# STM32H7S register map
File version: 1.3
CPU: CM7 r0p1, little endian, MPU, FPU, 4 interrupt priority bits
Registers are 32-bit, read-write, reset 0x0 unless marked. A register's access mark holds for its fields unless they carry their own. Offsets are from the block's base; [hi:lo] are bit positions; {n}, {i} and the like mark numbered series; 'fields as' and 'values as' point back to an identical list; <NAME> marks a mode.

## RCC — RCC register block
Base 0x58024400
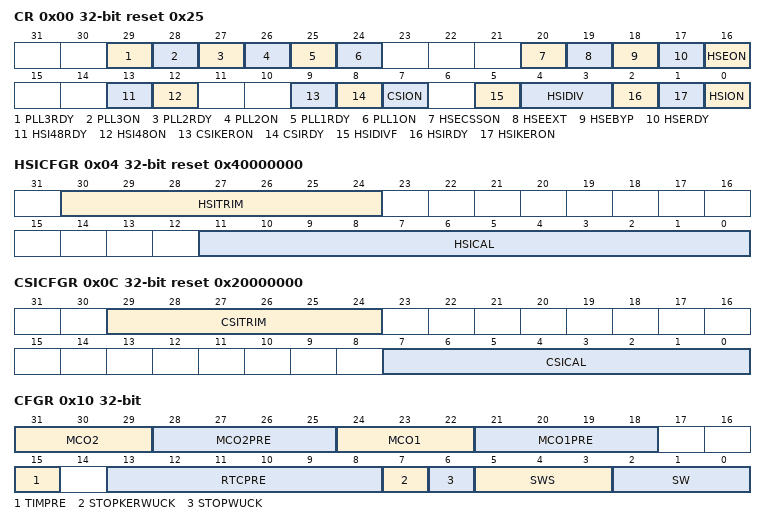
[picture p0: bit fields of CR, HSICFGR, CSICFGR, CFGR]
0x00 CR reset 0x25 — RCC source control register
  [29] PLL3RDY ro — PLL3 clock ready flag
    0=NotReady (Clock not ready); 1=Ready (Clock ready)
  [28] PLL3ON — PLL3 enable
    0=Off (Clock Off); 1=On (Clock On)
  [27] PLL2RDY ro — PLL2 clock ready flag
    0=NotReady (Clock not ready); 1=Ready (Clock ready)
  [26] PLL2ON — PLL2 enable
    0=Off (Clock Off); 1=On (Clock On)
  [25] PLL1RDY ro — PLL1 clock ready flag
    0=NotReady (Clock not ready); 1=Ready (Clock ready)
  [24] PLL1ON — PLL1 enable
    0=Off (Clock Off); 1=On (Clock On)
  [20] HSECSSON — HSE clock security system enable
    0=Off (Clock Off); 1=On (Clock On)
  [19] HSEEXT — external high speed clock type in Bypass mode
  [18] HSEBYP — HSE clock bypass
    0=NotBypassed (HSE crystal oscillator not bypassed); 1=Bypassed (HSE crystal oscillator bypassed with external clock)
  [17] HSERDY ro — HSE clock ready flag
    0=NotReady (Clock not ready); 1=Ready (Clock ready)
  [16] HSEON — HSE clock enable
    0=Off (Clock Off); 1=On (Clock On)
  [13] HSI48RDY ro — HSI48 clock ready flag
    0=NotReady (Clock not ready); 1=Ready (Clock ready)
  [12] HSI48ON — HSI48 clock enable
    0=Off (Clock Off); 1=On (Clock On)
  [9] CSIKERON — CSI clock enable in Stop mode
    0=Off (Clock Off); 1=On (Clock On)
  [8] CSIRDY ro — CSI clock ready flag
    0=NotReady (Clock not ready); 1=Ready (Clock ready)
  [7] CSION — CSI clock enable
    0=Off (Clock Off); 1=On (Clock On)
  [5] HSIDIVF ro — HSI divider flag
    0=NotPropagated (New HSIDIV ratio has not yet propagated to hsi_ck); 1=Propagated (HSIDIV ratio has propagated to hsi_ck)
  [4:3] HSIDIV — HSI clock divider
    0=Div1 (No division); 1=Div2 (Division by 2); 2=Div4 (Division by 4); 3=Div8 (Division by 8)
  [2] HSIRDY ro — HSI clock ready flag
    0=NotReady (Clock not ready); 1=Ready (Clock ready)
  [1] HSIKERON — HSI clock enable in Stop mode
    0=Off (Clock Off); 1=On (Clock On)
  [0] HSION — HSI clock enable
    0=Off (Clock Off); 1=On (Clock On)
0x04 HSICFGR reset 0x40000000 (reset mask 0xFFFFF000) — RCC HSI calibration register
  [30:24] HSITRIM — HSI clock trimming
  [11:0] HSICAL ro — HSI clock calibration
0x08 CRRCR ro (reset mask 0xFFFFF000) — RCC clock recovery RC register
  [9:0] HSI48CAL — Internal RC 48 MHz clock calibration
0x0C CSICFGR reset 0x20000000 (reset mask 0xFFFFF000) — RCC CSI calibration register
  [29:24] CSITRIM — CSI clock trimming
  [7:0] CSICAL ro — CSI clock calibration
0x10 CFGR — RCC clock configuration register
  [31:29] MCO2 — microcontroller clock output 2
    0=SYSCLK (System clock selected for micro-controller clock output); 1=PLL2_P (pll2_p selected for micro-controller clock output); 2=HSE (HSE selected for micro-controller clock output); 3=PLL1_P (pll1_p selected for micro-controller clock output); 4=CSI (CSI selected for micro-controller clock output); 5=LSI (LSI selected for micro-controller clock output)
  [28:25] MCO2PRE — MCO2 prescaler
  [24:22] MCO1 — Microcontroller clock output 1
    0=HSI (HSI selected for micro-controller clock output); 1=LSE (LSE selected for micro-controller clock output); 2=HSE (HSE selected for micro-controller clock output); 3=PLL1_Q (pll1_q selected for micro-controller clock output); 4=HSI48 (HSI48 selected for micro-controller clock output)
  [21:18] MCO1PRE — MCO1 prescaler
  [15] TIMPRE — timers clocks prescaler selection
    0=DefaultX2 (Timer kernel clock equal to 2x pclk by default); 1=DefaultX4 (Timer kernel clock equal to 4x pclk by default)
  [13:8] RTCPRE — HSE division factor for RTC clock
  [7] STOPKERWUCK — kernel clock selection after a wake up from system Stop
    0=HSI (HSI selected as wake up clock from system Stop); 1=CSI (CSI selected as wake up clock from system Stop)
  [6] STOPWUCK — system clock selection after a wake up from system Stop
    values as STOPKERWUCK
  [5:3] SWS ro — system clock switch status
    0=HSI (HSI oscillator used as system clock); 1=CSI (CSI oscillator used as system clock); 2=HSE (HSE oscillator used as system clock); 3=PLL1 (PLL1 used as system clock)
  [2:0] SW — system clock switch
    0=HSI (HSI selected as system clock); 1=CSI (CSI selected as system clock); 2=HSE (HSE selected as system clock); 3=PLL1 (PLL1 selected as system clock)
0x18 CDCFGR — RCC CPU domain clock configuration register
  [3:0] CPRE — CPU domain core prescaler
0x1C BMCFGR — RCC AHB clock configuration register
  [3:0] HPRE — Bus matrix clock prescaler
    8=Div2 (sys_ck divided by 2); 9=Div4 (sys_ck divided by 4); 10=Div8 (sys_ck divided by 8); 11=Div16 (sys_ck divided by 16); 12=Div64 (sys_ck divided by 64); 13=Div128 (sys_ck divided by 128); 14=Div256 (sys_ck divided by 256); 15=Div512 (sys_ck divided by 512); other=Div1 (sys_ck not divided)
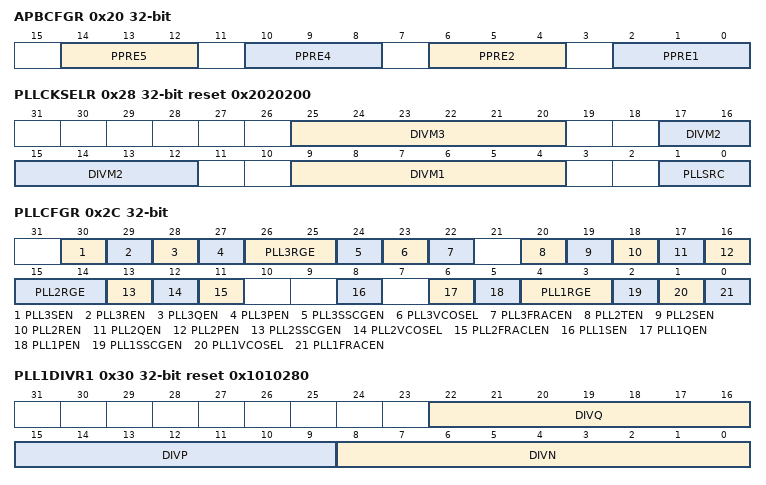
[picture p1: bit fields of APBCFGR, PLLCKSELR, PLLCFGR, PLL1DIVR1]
0x20 APBCFGR — RCC APB clocks configuration register
  [14:12] PPRE5 — CPU domain APB5 prescaler
  [10:8] PPRE4 — CPU domain APB4 prescaler
  [6:4] PPRE2 — CPU domain APB2 prescaler
  [2:0] PPRE1 — CPU domain APB1 prescaler
0x28 PLLCKSELR reset 0x2020200 — RCC PLLs clock source selection register
  [25:20] DIVM3 — prescaler for PLL3
  [17:12] DIVM2 — prescaler for PLL2
  [9:4] DIVM1 — prescaler for PLL1
  [1:0] PLLSRC — DIVMx and PLLs clock source selection
    0=HSI (HSI selected as PLL clock); 1=CSI (CSI selected as PLL clock); 2=HSE (HSE selected as PLL clock); 3=None (No clock sent to DIVMx dividers and PLLs)
0x2C PLLCFGR — RCC PLLs configuration register
  [30] PLL3SEN — PLL3 DIVS divider output enable
    0=Disabled (Clock ouput is disabled); 1=Enabled (Clock output is enabled)
  [29] PLL3REN — PLL3 DIVR divider output enable
    values as PLL3SEN
  [28] PLL3QEN — PLL3 DIVQ divider output enable
    values as PLL3SEN
  [27] PLL3PEN — PLL3 DIVP divider output enable
    values as PLL3SEN
  [26:25] PLL3RGE — PLL3 input frequency range
    0=Range1 (Frequency is between 1 and 2 MHz); 1=Range2 (Frequency is between 2 and 4 MHz); 2=Range4 (Frequency is between 4 and 8 MHz); 3=Range8 (Frequency is between 8 and 16 MHz)
  [24] PLL3SSCGEN — PLL3 SSCG enable
  [23] PLL3VCOSEL — PLL3 VCO selection
    0=WideVCO (VCO frequency range 192 to 836 MHz); 1=MediumVCO (VCO frequency range 150 to 420 MHz)
  [22] PLL3FRACEN — PLL3 fractional latch enable
    0=Reset latch to tranfer FRACN to the Sigma-Delta modulator; 1=Set (Set latch to tranfer FRACN to the Sigma-Delta modulator)
  [20] PLL2TEN — PLL2 DIVT divider output enable
    values as PLL3SEN
  [19] PLL2SEN — PLL2 DIVS divider output enable
    values as PLL3SEN
  [18] PLL2REN — PLL2 DIVR divider output enable
    values as PLL3SEN
  [17] PLL2QEN — PLL2 DIVQ divider output enable
    values as PLL3SEN
  [16] PLL2PEN — PLL2 DIVP divider output enable
    values as PLL3SEN
  [15:14] PLL2RGE — PLL2 input frequency range
    values as PLL3RGE
  [13] PLL2SSCGEN — PLL2 SSCG enable
  [12] PLL2VCOSEL — PLL2 VCO selection
    values as PLL3VCOSEL
  [11] PLL2FRACLEN — PLL2 fractional latch enable
  [8] PLL1SEN — PLL1 DIVS divider output enable
    values as PLL3SEN
  [6] PLL1QEN — PLL1 DIVQ divider output enable
    values as PLL3SEN
  [5] PLL1PEN — PLL1 DIVP divider output enable
    values as PLL3SEN
  [4:3] PLL1RGE — PLL1 input frequency range
    values as PLL3RGE
  [2] PLL1SSCGEN — PLL1 SSCG enable
  [1] PLL1VCOSEL — PLL1 VCO selection
    values as PLL3VCOSEL
  [0] PLL1FRACEN — PLL1 fractional latch enable
    values as PLL3FRACEN
0x30 PLL1DIVR1 reset 0x1010280 — RCC PLL1 dividers configuration register 1
  [22:16] DIVQ — PLL1 DIVQ division factor
  [15:9] DIVP — PLL1 DIVP division factor
  [8:0] DIVN — multiplication factor for PLL1 VCO
{0x2C+8i} PLL{i}FRACR (i=1..3) — RCC PLL{i} fractional divider register
  [15:3] FRACN — fractional part of the multiplication factor for PLL{i} VCO
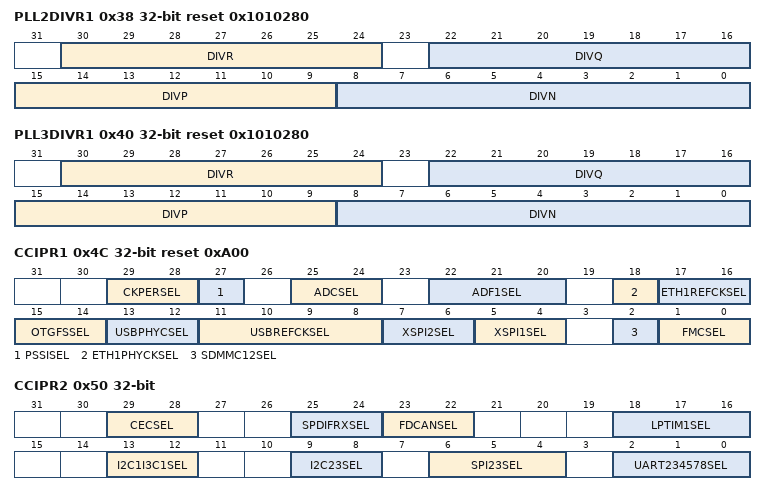
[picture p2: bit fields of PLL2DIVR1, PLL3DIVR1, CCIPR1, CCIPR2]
0x38 PLL2DIVR1 reset 0x1010280 — RCC PLL2 dividers configuration register 1
  [30:24] DIVR — PLL2 DIVR division factor
  [22:16] DIVQ — PLL2 DIVQ division factor
  [15:9] DIVP — PLL2 DIVP division factor
  [8:0] DIVN — multiplication factor for PLL2 VCO
0x40 PLL3DIVR1 reset 0x1010280 — RCC PLL3 dividers configuration register 1
  [30:24] DIVR — PLL3 DIVR division factor
  [22:16] DIVQ — PLL3 DIVQ division factor
  [15:9] DIVP — PLL3 DIVP division factor
  [8:0] DIVN — Multiplication factor for PLL3 VCO
0x4C CCIPR1 reset 0xA00 — RCC AHB peripheral kernel clock selection register
  [29:28] CKPERSEL — per_ck clock source selection
    0=HSI (HSI selected as peripheral clock); 1=CSI (CSI selected as peripheral clock); 2=HSE (HSE selected as peripheral clock)
  [27] PSSISEL — PSSI kernel clock source selection
    0=PLL3_R (pll3_r selected as peripheral clock); 1=PER (per selected as kernel peripheral clock)
  [25:24] ADCSEL — SAR ADC kernel clock source selection
    0=PLL2_P (pll2_p selected as peripheral clock); 1=PLL3_R (pll3_r selected as peripheral clock); 2=PER (per selected as peripheral clock)
  [22:20] ADF1SEL — ADF kernel clock source selection
    0=HCLK1 (hclk1 selected as ADF clock); 1=pll2_p_ck selected as ADF clock; 2=PLL3_P (pll3_p_ck selected as ADF clock); 3=I2S_CLKIN (I2S_CKIN selected as ADF clock); 4=CSI_KER (csi_ker_ck selected as ADF clock); 5=HSI_KER (hsi_ker_ck selected as ADF clock)
  [18] ETH1PHYCKSEL — Clock source selection for external Ethernet PHY
    0=HSE_KER (hse_ker selected as clock source); 1=PLL3_S (pll3_s selected clock source)
  [17:16] ETH1REFCKSEL — Ethernet reference clock source selection
    0=ETH_RMII_REF (ETH_RMII_REF selected as peripheral clock); 1=HSE_KER (hse_ker selected as peripheral clock); 2=ETH_CLK_FB (eth_clk_fb selected as peripheral clock)
  [15:14] OTGFSSEL — OTGFS kernel clock source selection
    0=HSI48_KER (hsi48_ker_ck); 1=PLL3_Q (pll3_q_ck); 2=HSE_KER (hse_ker_ck); 3=CLK48 (clk48mohci)
  [13:12] USBPHYCSEL — USBPHYC kernel clock source selection
    0=HSE_KER (hse_ker_ck); 1=HSE_KER_DIV2 (hse_ker_ck / 2); 2=PLL3_Q (pll3_q_ck)
  [11:8] USBREFCKSEL — USBPHYC kernel clock frequency selection
    3=MHz16 (The clock frequency provided to the USBPHYC is 16 MHz); 8=MHz19 (The clock frequency provided to the USBPHYC is 19.2 MHz); 9=MHz20 (The clock frequency provided to the USBPHYC is 20MHz); 10=MHz24 (The clock frequency provided to the USBPHYC is 24 MHz); 11=MHz32 (The clock frequency provided to the USBPHYC is 32 MHz); 14=MHz26 (The clock frequency provided to the USBPHYC is 26 MHz)
  [7:6] XSPI2SEL — XSPI2 kernel clock source selection
    0=RCC_HCLK5 (hclk5 selected as peripheral clock); 1=PLL2_S (pll2_s_ck selected as peripheral clock); 2=PLL2_T (pll2_t_ck selected as peripheral clock)
  [5:4] XSPI1SEL — XSPI1 kernel clock source selection
    values as XSPI2SEL
  [2] SDMMC12SEL — SDMMC1 and SDMMC2 kernel clock source selection
    0=PLL2_S (pll1_s selected as peripheral clock); 1=PLL2_T (pll2_t selected as peripheral clock)
  [1:0] FMCSEL — FMC kernel clock source selection
    0=RCC_HCLK5 (hclk5 selected as peripheral clock); 1=PLL1_Q (pll1_q selected as peripheral clock); 2=PLL2_R (pll2_r selected as peripheral clock); 3=HSI_KER (hsi_ker selected as peripheral clock)
0x50 CCIPR2 — RCC APB1 peripherals kernel clock selection register
  [29:28] CECSEL — HDMI-CEC kernel clock source selection
    0=LSE (lse selected as clock); 1=LSI (lsi selected as clock); 2=CSI_KER (csi_ker divided by 122 selected as clock)
  [25:24] SPDIFRXSEL — SPDIFRX kernel clock source selection
    0=PLL1_Q (pll1_q selected as clock); 1=PLL2_R (pll2_r selected as clock); 2=PLL3_R (pll3_r selected as clock); 3=HSI_KER (hsi_ker selected as clock)
  [23:22] FDCANSEL — FDCAN kernel clock source selection
    0=HSE_KER (hse_ker selected as clock); 1=PLL1_Q (pll1_q selected as clock); 2=PLL2_P (pll2_p selected as clock)
  [18:16] LPTIM1SEL — LPTIM1 kernel clock source selection
    0=PCLK1 (pclk1 selected as peripheral clock); 1=PLL2_P (pll2_p selected as peripheral clock); 2=PLL3_R (pll3_r selected as peripheral clock); 3=LSE (lse selected as peripheral clock); 4=LSI (lsi selected as peripheral clock); 5=PER (per selected as peripheral clock)
  [13:12] I2C1I3C1SEL — I2C1 or I3C1 kernel clock source selection
    0=PCLK1 (pclk1 selected as peripheral clock); 1=PLL3_R (pll3_r selected as peripheral clock); 2=HSI_KER (hsi_ker selected as peripheral clock); 3=CSI_KER (csi_ker selected as peripheral clock)
  [9:8] I2C23SEL — I2C2, I2C3 kernel clock source selection
    0=PCLK1 (pclk1 selected as clock); 1=PLL3_R (pll3_r selected as clock); 2=HSI_KER (hsi_ker selected as clock); 3=CSI_KER (csi_ker selected as clock)
  [6:4] SPI23SEL — SPI/I2S2 and SPI/I2S3 kernel clock source selection
    0=PLL1_Q (pll1_q selected as clock); 1=PLL2_P (pll2_p selected as clock); 2=PLL3_P (pll3_p selected as clock); 3=I2S_CKIN (I2S_CKIN selected as clock); 4=PER (per selected as clock)
  [2:0] UART234578SEL — USART2,3, UART4,5,7,8 (APB1) kernel clock source selection
    0=PCLK1 (pclk1 selected as clock); 1=PLL2_Q (pll2_q selected as clock); 2=PLL3_Q (pll3_q selected as clock); 3=HSI_KER (hsi_ker selected as clock); 4=CSI_KER (csi_ker selected as clock); 5=LSE (lse selected as clock)
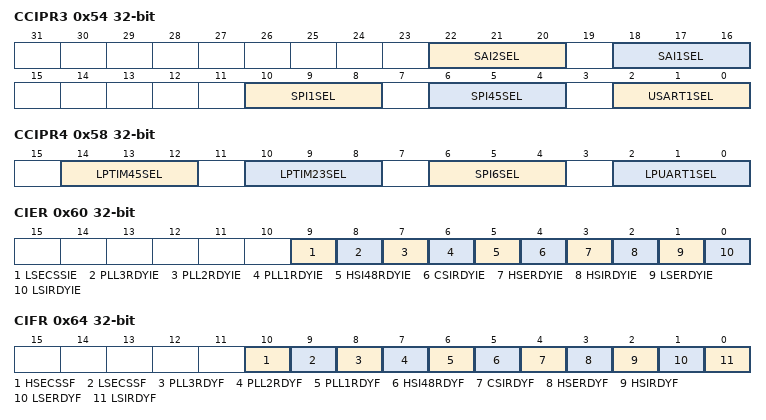
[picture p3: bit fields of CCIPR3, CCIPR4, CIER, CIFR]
0x54 CCIPR3 — RCC APB2 peripherals kernel clock selection register
  [22:20] SAI2SEL — SAI2 kernel clock source selection
    0=PLL1_Q (pll1_q selected as clock); 1=PLL2_P (pll2_p selected as clock); 2=PLL3_P (pll3_p selected as clock); 3=I2S_CKIN (I2S_CKIN selected as clock); 4=PER (per selected as clock); 5=SPDIFRX_SYMB (spdifrx_symb selected as clock)
  [18:16] SAI1SEL — SAI1 kernel clock source selection
    values as CCIPR2.SPI23SEL
  [10:8] SPI1SEL — SPI/I2S1 kernel clock source selection
    0=PLL1_Q (pll1_q selected as SPI/I2S1 and 7 clock); 1=PLL2_P (pll2_p selected as SPI/I2S1 and 7 clock); 2=PLL3_P (pll3_p selected as SPI/I2S1 and 7 clock); 3=I2S_CKIN (I2S_CKIN selected as SPI/I2S1 and 7 clock); 4=PER (per selected as SPI/I2S1,and 7 clock)
  [6:4] SPI45SEL — SPI4 and 5 kernel clock source selection
    0=PCLK2 (pclk2 selected as clock); 1=PLL2_Q (pll2_q is selected as clock); 2=PLL3_Q (pll3_q is selected as clock); 3=HSI_KER (hsi_ker is selected as clock); 4=CSI_KER (csi_ker is selected as clock); 5=HSE_KER (hse_ker is selected as clock)
  [2:0] USART1SEL — USART1 kernel clock source selection
    0=PCLK2 (pclk2 selected as clock); 1=PLL2_Q (pll2_q selected as clock); 2=PLL3_Q (pll3_q selected as clock); 3=HSI_KER (hsi_ker selected as clock); 4=CSI_KER (csi_ker selected as clock); 5=LSE (lse selected as clock)
0x58 CCIPR4 — RCC APB4,5 peripherals kernel clock selection register
  [14:12] LPTIM45SEL — LPTIM4, and LPTIM5 kernel clock source selection
    0=PCLK4 (pclk4 selected as peripheral clock); 1=PLL2_P (pll2_p selected as peripheral clock); 2=PLL3_R (pll3_r selected as peripheral clock); 3=LSE (lse selected as peripheral clock); 4=LSI (lsi selected as peripheral clock); 5=PER (per selected as peripheral clock)
  [10:8] LPTIM23SEL — LPTIM2 and LPTIM3 kernel clock source selection
    values as LPTIM45SEL
  [6:4] SPI6SEL — SPI/I2S6 kernel clock source selection
    0=PCLK4 (pclk4 selected as peripheral clock); 1=PLL2_Q (pll2_q selected as peripheral clock); 2=PLL3_Q (pll3_q selected as peripheral clock); 3=HSI_KER (hsi_ker selected as peripheral clock); 4=CSI_KER (csi_ker selected as peripheral clock); 5=HSE_KER (hse_ker selected as peripheral clock)
  [2:0] LPUART1SEL — LPUART1 kernel clock source selection
    0=PCLK4 (pclk4 selected as peripheral clock); 1=PLL2_Q (pll2_q selected as peripheral clock); 2=PLL3_Q (pll3_q selected as peripheral clock); 3=HSI_KER (hsi_ker selected as peripheral clock); 4=CSI_KER (csi_ker selected as peripheral clock); 5=LSE (lse selected as peripheral clock)
0x60 CIER — RCC clock source interrupt enable register
  [all] fields
    0=Disabled (Interrupt disabled); 1=Enabled (Interrupt enabled)
  [9] LSECSSIE — LSE clock security system interrupt enable
  [8] PLL3RDYIE — PLL3 ready interrupt enable
  [7] PLL2RDYIE — PLL2 ready interrupt enable
  [6] PLL1RDYIE — PLL1 ready interrupt enable
  [5] HSI48RDYIE — HSI48 ready interrupt enable
  [4] CSIRDYIE — CSI ready interrupt enable
  [3] HSERDYIE — HSE ready interrupt enable
  [2] HSIRDYIE — HSI ready interrupt enable
  [1] LSERDYIE — LSE ready interrupt enable
  [0] LSIRDYIE — LSI ready interrupt enable
0x64 CIFR ro — RCC clock source interrupt flag register
  [10] HSECSSF — HSE clock security system interrupt flag
  [9] LSECSSF — LSE clock security system interrupt flag
  [8] PLL3RDYF — PLL3 ready interrupt flag
    0=NotInterrupted (No clock ready interrupt); 1=Interrupted (Clock ready interrupt)
  [7] PLL2RDYF — PLL2 ready interrupt flag
    values as PLL3RDYF
  [6] PLL1RDYF — PLL1 ready interrupt flag
    values as PLL3RDYF
  [5] HSI48RDYF — HSI48 ready interrupt flag
    values as PLL3RDYF
  [4] CSIRDYF — CSI ready interrupt flag
    values as PLL3RDYF
  [3] HSERDYF — HSE ready interrupt flag
    values as PLL3RDYF
  [2] HSIRDYF — HSI ready interrupt flag
    values as PLL3RDYF
  [1] LSERDYF — LSE ready interrupt flag
    values as PLL3RDYF
  [0] LSIRDYF — LSI ready interrupt flag
    values as PLL3RDYF
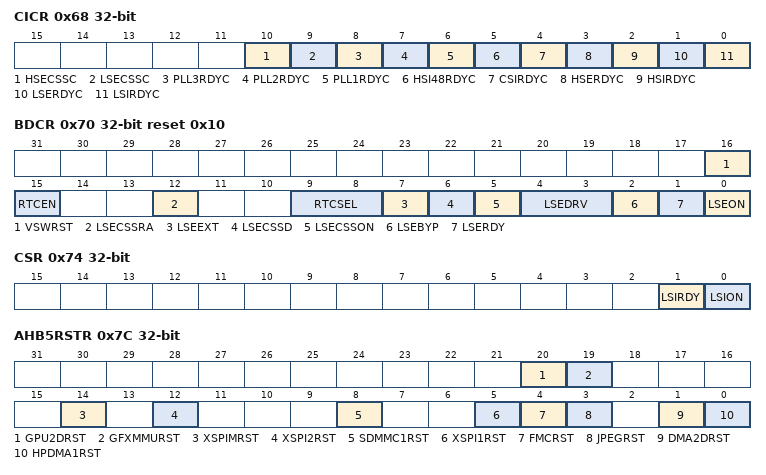
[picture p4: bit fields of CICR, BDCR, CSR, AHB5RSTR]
0x68 CICR — RCC clock source interrupt clear register
  [all] fields
    1=Clear interrupt flag
  [10] HSECSSC — HSE clock security system interrupt clear
  [9] LSECSSC — LSE clock security system interrupt clear
  [8] PLL3RDYC — PLL3 ready interrupt clear
  [7] PLL2RDYC — PLL2 ready interrupt clear
  [6] PLL1RDYC — PLL1 ready interrupt clear
  [5] HSI48RDYC — HSI48 ready interrupt clear
  [4] CSIRDYC — CSI ready interrupt clear
  [3] HSERDYC — HSE ready interrupt clear
  [2] HSIRDYC — HSI ready interrupt clear
  [1] LSERDYC — LSE ready interrupt clear
  [0] LSIRDYC — LSI ready interrupt clear
0x70 BDCR rw-once reset 0x10 — RCC Backup domain control register
  [16] VSWRST rw — VSwitch domain software reset
    0=NotActivated (Reset not activated); 1=Resets the entire VSW domain
  [15] RTCEN rw — RTC clock enable
    0=Disabled (RTC clock disabled); 1=Enabled (RTC clock enabled)
  [12] LSECSSRA rw — Re-Arm the LSECSS function
  [9:8] RTCSEL — RTC clock source selection
    0=NoClock; 1=LSE (LSE oscillator clock used as RTC clock); 2=LSI (LSI oscillator clock used as RTC clock); 3=HSE (HSE oscillator clock divided by a prescaler used as RTC clock)
  [7] LSEEXT rw — low-speed external clock type in Bypass mode
  [6] LSECSSD ro — LSE clock security system failure detection
    0=No failure detected on 32 kHz oscillator; 1=Failure detected on 32 kHz oscillator
  [5] LSECSSON rw — LSE clock security system enable
    0=SecurityOff (Clock security system on 32 kHz oscillator off); 1=SecurityOn (Clock security system on 32 kHz oscillator on)
  [4:3] LSEDRV rw — LSE oscillator driving capability
    0=Lowest LSE oscillator driving capability; 1=Medium low LSE oscillator driving capability; 2=Medium high LSE oscillator driving capability; 3=Highest LSE oscillator driving capability
  [2] LSEBYP rw — LSE oscillator bypass
    0=NotBypassed (LSE crystal oscillator not bypassed); 1=Bypassed (LSE crystal oscillator bypassed with external clock)
  [1] LSERDY ro — LSE oscillator ready
    0=NotReady (LSE oscillator not ready); 1=Ready (LSE oscillator ready)
  [0] LSEON rw — LSE oscillator enabled
    0=Off (LSE oscillator Off); 1=On (LSE oscillator On)
0x74 CSR — RCC clock control and status register
  [1] LSIRDY ro — LSI oscillator ready
    0=NotReady (LSI oscillator not ready); 1=Ready (LSI oscillator ready)
  [0] LSION — LSI oscillator enable
    0=Off (LSI oscillator Off); 1=On (LSI oscillator On)
0x7C AHB5RSTR — RCC AHB5 peripheral reset register
  [all] fields
    1=Reset the selected module
  [20] GPU2DRST — GPU2D block reset
  [19] GFXMMURST — GFXMMU block reset
  [14] XSPIMRST — XSPIM reset
  [12] XSPI2RST — XSPI2 and MCE2 blocks reset
  [8] SDMMC1RST — SDMMC1 and DB_SDMMC1 blocks reset
  [5] XSPI1RST — XSPI1 and MCE1 blocks reset
  [4] FMCRST — FMC and MCE3 blocks reset
  [3] JPEGRST — JPEG block reset
  [1] DMA2DRST — DMA2D block reset
  [0] HPDMA1RST — HPDMA1 block reset
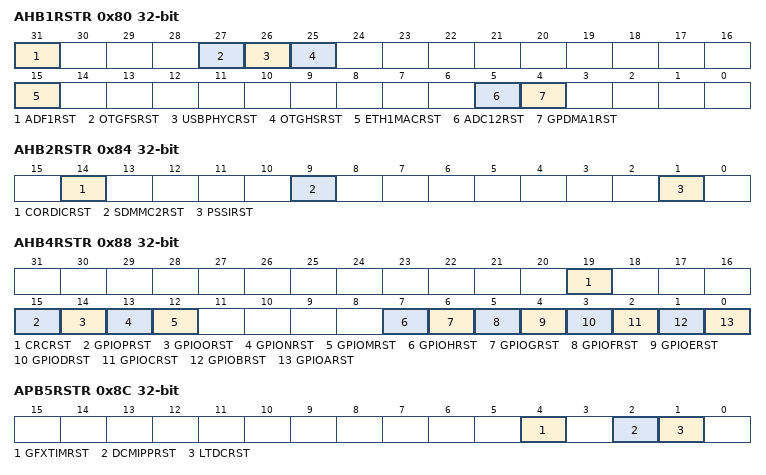
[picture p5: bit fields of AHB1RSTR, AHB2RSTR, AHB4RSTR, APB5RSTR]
0x80 AHB1RSTR — RCC AHB1 peripheral reset register
  [all] fields
    1=Reset the selected module
  [31] ADF1RST — ADF block reset
  [27] OTGFSRST — OTGFS block reset
  [26] USBPHYCRST — USBPHYC block reset
  [25] OTGHSRST — OTGHS block reset
  [15] ETH1MACRST — ETH1 block reset
  [5] ADC12RST — ADC1 and 2 blocks reset
  [4] GPDMA1RST — GPDMA1 blocks reset
0x84 AHB2RSTR — RCC AHB2 peripheral reset register
  [all] fields
    1=Reset the selected module
  [14] CORDICRST — CORDIC reset
  [9] SDMMC2RST — SDMMC2 and SDMMC2 delay blocks reset
  [1] PSSIRST — PSSI block reset
0x88 AHB4RSTR — RCC AHB4 peripheral reset register
  [all] fields
    1=Reset the selected module
  [19] CRCRST — CRC block reset
  [15] GPIOPRST — GPIOP block reset
  [14] GPIOORST — GPIOO block reset
  [13] GPIONRST — GPION block reset
  [12] GPIOMRST — GPIOM block reset
  [7] GPIOHRST — GPIOH block reset
  [6] GPIOGRST — GPIOG block reset
  [5] GPIOFRST — GPIOF block reset
  [4] GPIOERST — GPIOE block reset
  [3] GPIODRST — GPIOD block reset
  [2] GPIOCRST — GPIOC block reset
  [1] GPIOBRST — GPIOB block reset
  [0] GPIOARST — GPIOA block reset
0x8C APB5RSTR — RCC APB5 peripheral reset register
  [all] fields
    1=Reset the selected module
  [4] GFXTIMRST — GFXTIM block reset
  [2] DCMIPPRST — DCMIPP block reset
  [1] LTDCRST — LTDC block reset
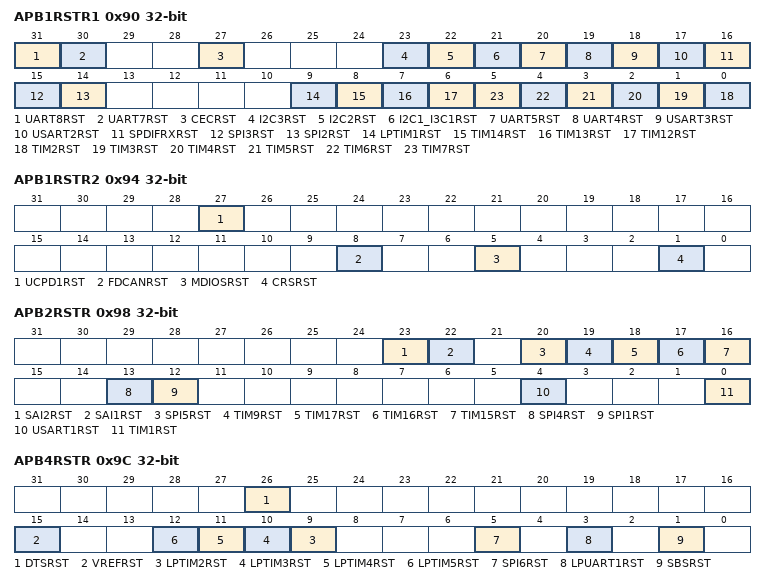
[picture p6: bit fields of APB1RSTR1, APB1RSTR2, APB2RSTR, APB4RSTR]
0x90 APB1RSTR1 — RCC APB1 peripheral reset register 1
  [31] UART8RST — UART8 block reset
  [30] UART7RST — UART7 block reset
  [27] CECRST — HDMI-CEC block reset
  [23] I2C3RST — I2C3 block reset
  [22] I2C2RST — I2C2 block reset
  [21] I2C1_I3C1RST — I2C1/I3C1 block reset
  [20] UART5RST — UART5 block reset
  [19] UART4RST — UART4 block reset
  [18] USART3RST — USART3 block reset
  [17] USART2RST — USART2 block reset
  [16] SPDIFRXRST — SPDIFRX block reset
  [15] SPI3RST — SPI2S3 block reset
  [14] SPI2RST — SPI2S2 block reset
  [9] LPTIM1RST — LPTIM1 block reset
  [8] TIM14RST — TIM14 block reset
  [7] TIM13RST — TIM13 block reset
  [6] TIM12RST — TIM12 block reset
  [n-2] TIM{n}RST (n=2..7) — TIM{n} block reset
0x94 APB1RSTR2 — RCC APB1 peripheral reset register 2
  [27] UCPD1RST — UCPD block reset
  [8] FDCANRST — FDCAN block reset
  [5] MDIOSRST — MDIOS block reset
  [1] CRSRST — clock recovery system reset
0x98 APB2RSTR — RCC APB2 peripheral reset register
  [all] fields
    1=Reset the selected module
  [23] SAI2RST — SAI2 block reset
  [22] SAI1RST — SAI1 block reset
  [20] SPI5RST — SPI5 block reset
  [19] TIM9RST — TIM9 block reset
  [18] TIM17RST — TIM17 block reset
  [17] TIM16RST — TIM16 block reset
  [16] TIM15RST — TIM15 block reset
  [13] SPI4RST — SPI4 block reset
  [12] SPI1RST — SPI2S1 block reset
  [4] USART1RST — USART1 block reset
  [0] TIM1RST — TIM1 block reset
0x9C APB4RSTR — RCC APB4 peripheral reset register
  [all] fields
    1=Reset the selected module
  [26] DTSRST — DTS block reset
  [15] VREFRST — VREF block reset
  [n+7] LPTIM{n}RST (n=2..5) — LPTIM{n} block reset
  [5] SPI6RST — SPI/I2S6 block reset
  [3] LPUART1RST — LPUART1 block reset
  [1] SBSRST — SBS block reset
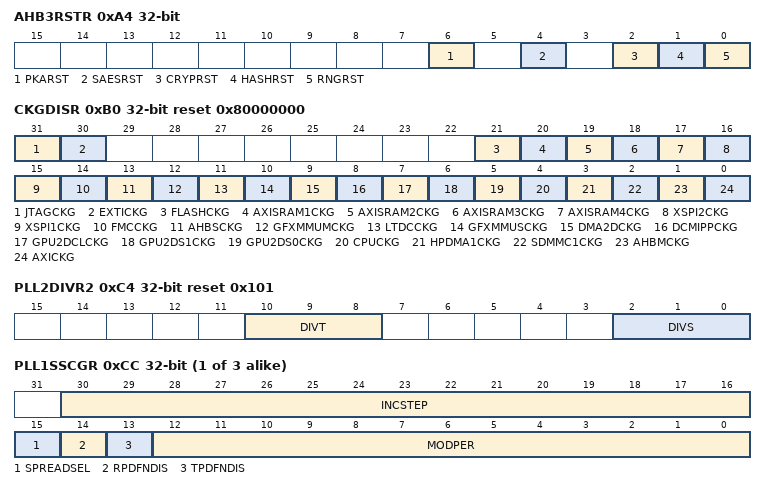
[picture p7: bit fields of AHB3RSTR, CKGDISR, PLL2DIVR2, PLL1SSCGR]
0xA4 AHB3RSTR — RCC AHB3 peripheral reset register
  [all] fields
    1=Reset the selected module
  [6] PKARST — PKA block reset
  [4] SAESRST — SAES block reset
  [2] CRYPRST — CRYP block reset
  [1] HASHRST — HASH block reset
  [0] RNGRST — random number generator block reset
0xB0 CKGDISR reset 0x80000000 — RCC AXI clocks gating disable register
  [31] JTAGCKG — JTAG automatic clock gating disabling
  [30] EXTICKG — EXTI clock gating disable
  [21] FLASHCKG — AXI slave Flash interface (FLIFT) clock gating disable
  [20] AXISRAM1CKG — AXI slave SRAM1 / error code correction (ECC) clock gating disable
  [19] AXISRAM2CKG — AXI slave SRAM2 clock gating disable
  [18] AXISRAM3CKG — AXI matrix slave SRAM3 clock gating disable
  [17] AXISRAM4CKG — AXI matrix slave SRAM4 clock gating disable
  [16] XSPI2CKG — AXI slave XSPI2 and MCE2 clock gating disable
  [15] XSPI1CKG — AXI slave XSPI1 and MCE1 clock gating disable
  [14] FMCCKG — AXI slave FMC and MCE3 clock gating disable
  [13] AHBSCKG — AXI slave AHB clock gating disable
  [12] GFXMMUMCKG — AXI master GFXMMU clock gating disable
  [11] LTDCCKG — AXI master LTDC clock gating disable
  [10] GFXMMUSCKG — AXI matrix slave GFXMMU clock gating disable
  [9] DMA2DCKG — AXI master DMA2D clock gating disable
  [8] DCMIPPCKG — AXI master DCMIPP clock gating disable
  [7] GPU2DCLCKG — AXI master cache GPU2D clock gating disable
  [6] GPU2DS1CKG — AXI master 1 GPU2D clock gating disable
  [5] GPU2DS0CKG — AXI master 0 GPU2D clock gating disable
  [4] CPUCKG — AXI master CPU clock gating disable
  [3] HPDMA1CKG — AXI master HPDMA1 clock gating disable
  [2] SDMMC1CKG — AXI master SDMMC1 clock gating disable
  [1] AHBMCKG — AXI master AHB clock gating disable
  [0] AXICKG — AXI interconnect matrix clock gating disable
0xC0 PLL1DIVR2 reset 0x101 — RCC PLL1 dividers configuration register 2
  [2:0] DIVS — PLL1 DIVS division factor
0xC4 PLL2DIVR2 reset 0x101 — RCC PLL2 dividers configuration register 2
  [10:8] DIVT — PLL2 DIVT division factor
  [2:0] DIVS — PLL2 DIVS division factor
0xC8 PLL3DIVR2 reset 0x101 — RCC PLL3 dividers configuration register 2
  [2:0] DIVS — PLL3 DIVS division factor
{0xC8+4i} PLL{i}SSCGR (i=1..3) — RCC PLL{i} Spread Spectrum Clock Generator register
  [30:16] INCSTEP — Modulation Depth Adjustment for PLL{i}
  [15] SPREADSEL — Spread spectrum clock generator mode for PLL{i}
  [14] RPDFNDIS — Dithering RPDF noise control for PLL{i}
  [13] TPDFNDIS — Dithering TPDF noise control for PLL{i}
  [12:0] MODPER — Modulation Period Adjustment for PLL{i}
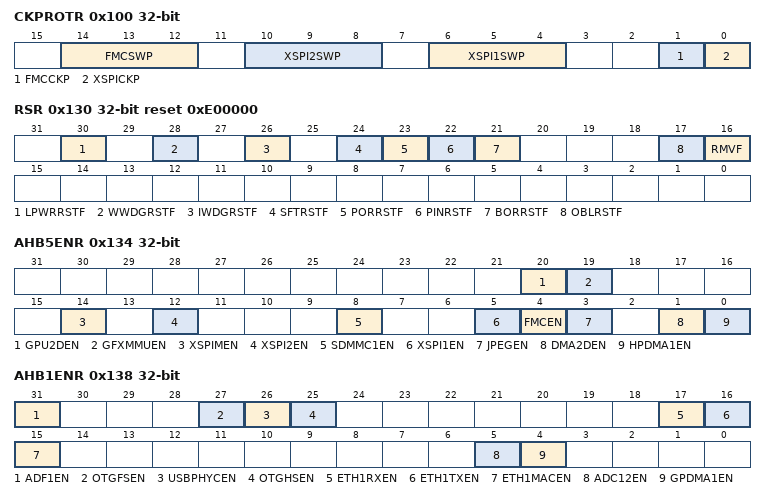
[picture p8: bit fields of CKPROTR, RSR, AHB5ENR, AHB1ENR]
0x100 CKPROTR — RCC clock protection register
  [14:12] FMCSWP ro — FMC kernel clock switch position
  [10:8] XSPI2SWP ro — XSPI2 kernel clock switch position
  [6:4] XSPI1SWP ro — XSPI1 kernel clock switch position
  [1] FMCCKP — FMC clock protection
  [0] XSPICKP — XSPI clock protection
0x130 RSR reset 0xE00000 — RCC Reset status register
  [30] LPWRRSTF ro — reset due to illegal Stop or Standby flag
    0=No reset occurred for block; 1=Reset occurred for block
  [28] WWDGRSTF ro — window watchdog reset flag <sup>(1)</sup>
    0=No reset occurred for block; 1=Reset occurred for block
  [26] IWDGRSTF ro — independent watchdog reset flag <sup>(1)</sup>
    0=No reset occurred for block; 1=Reset occurred for block
  [24] SFTRSTF ro — system reset from CPU reset flag <sup>(1)</sup>
    0=No reset occurred for block; 1=Reset occurred for block
  [23] PORRSTF ro — POR/PDR reset flag <sup>(1)</sup>
    0=No reset occurred for block; 1=Reset occurred for block
  [22] PINRSTF ro — pin reset flag (NRST) <sup>(1)</sup>
    0=No reset occurred for block; 1=Reset occurred for block
  [21] BORRSTF ro — BOR reset flag <sup>(1)</sup>
    0=No reset occurred for block; 1=Reset occurred for block
  [17] OBLRSTF ro — Option byte loading reset flag <sup>(1)</sup>
    0=No reset occurred for block; 1=Reset occurred for block
  [16] RMVF — remove reset flag
    0=NotActivated (Reset not activated); 1=Reset the reset status flags
0x134 AHB5ENR — RCC AHB5 clock enable register
  [all] fields
    0=Disabled (The selected clock is disabled); 1=Enabled (The selected clock is enabled)
  [20] GPU2DEN — GPU2D peripheral clock enable
  [19] GFXMMUEN — GFXMMU peripheral clock enable
  [14] XSPIMEN — XSPIM peripheral clock enable
  [12] XSPI2EN — XSPI2 and MCE2 peripheral clocks enable
  [8] SDMMC1EN — SDMMC1 and DB_SDMMC1 peripheral clocks enable
  [5] XSPI1EN — XSPI1 and MCE1 peripheral clocks enable
  [4] FMCEN — FMC and MCE3 peripheral clocks enable
  [3] JPEGEN — JPEG peripheral clock enable
  [1] DMA2DEN — DMA2D peripheral clock enable
  [0] HPDMA1EN — HPDMA1 peripheral clock enable
0x138 AHB1ENR — RCC AHB1 clock enable register
  [all] fields
    values as the fields of AHB5ENR
  [31] ADF1EN — ADF clocks enable
  [27] OTGFSEN — OTGFS peripheral clocks enable
  [26] USBPHYCEN — USBPHYC clocks enable
  [25] OTGHSEN — OTGHS clocks enable
  [17] ETH1RXEN — ETH1 reception clock enable
  [16] ETH1TXEN — ETH1 transmission clock enable
  [15] ETH1MACEN — ETH1 MAC peripheral clock enable
  [5] ADC12EN — ADC1 and 2 peripheral clocks enable
  [4] GPDMA1EN — GPDMA1 clock enable
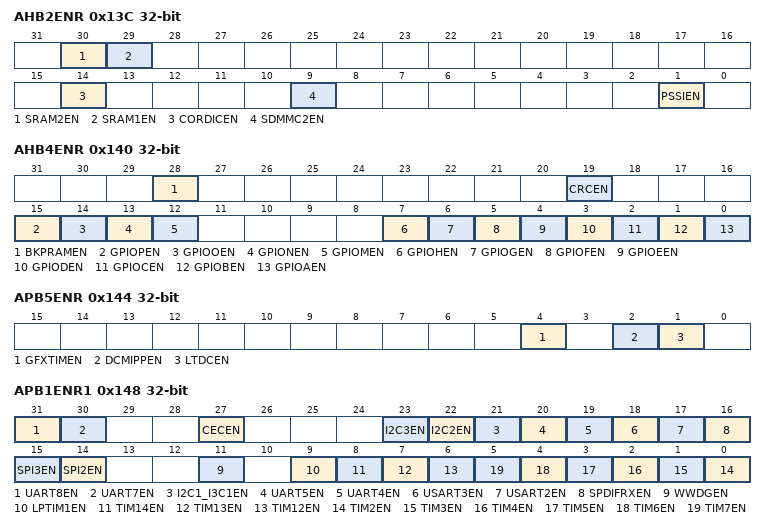
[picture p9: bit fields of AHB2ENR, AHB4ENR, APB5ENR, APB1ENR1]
0x13C AHB2ENR — RCC AHB2 clock enable register
  [all] fields
    values as the fields of AHB5ENR
  [30] SRAM2EN — SRAM2 clock enable
  [29] SRAM1EN — SRAM1 clock enable
  [14] CORDICEN — CORDIC clock enable
  [9] SDMMC2EN — SDMMC2 and SDMMC2 delay clock enable
  [1] PSSIEN — PSSI peripheral clocks enable
0x140 AHB4ENR — RCC AHB4 clock enable register
  [all] fields
    values as the fields of AHB5ENR
  [28] BKPRAMEN — Backup RAM clock enable
  [19] CRCEN — CRC clock enable
  [15] GPIOPEN — GPIOP peripheral clock enable
  [14] GPIOOEN — GPIOO peripheral clock enable
  [13] GPIONEN — GPION peripheral clock enable
  [12] GPIOMEN — GPIOM peripheral clock enable
  [7] GPIOHEN — GPIOH peripheral clock enable
  [6] GPIOGEN — GPIOG peripheral clock enable
  [5] GPIOFEN — GPIOF peripheral clock enable
  [4] GPIOEEN — GPIOE peripheral clock enable
  [3] GPIODEN — GPIOD peripheral clock enable
  [2] GPIOCEN — GPIOC peripheral clock enable
  [1] GPIOBEN — GPIOB peripheral clock enable
  [0] GPIOAEN — GPIOA peripheral clock enable
0x144 APB5ENR — RCC APB5 clock enable register
  [all] fields
    values as the fields of AHB5ENR
  [4] GFXTIMEN — GFXTIM peripheral clock enable
  [2] DCMIPPEN — DCMIPP peripheral clock enable
  [1] LTDCEN — LTDC peripheral clock enable
0x148 APB1ENR1 — RCC APB1 clock enable register 1
  [31] UART8EN — UART8 peripheral clocks enable
  [30] UART7EN — UART7 peripheral clocks enable
  [27] CECEN — HDMI-CEC peripheral clock enable
  [23] I2C3EN — I2C3 peripheral clocks enable
  [22] I2C2EN — I2C2 peripheral clocks enable
  [21] I2C1_I3C1EN — I2C1/I3C1 peripheral clocks enable
  [20] UART5EN — UART5 peripheral clocks enable
  [19] UART4EN — UART4 peripheral clocks enable
  [18] USART3EN — USART3 peripheral clocks enable
  [17] USART2EN — USART2peripheral clocks enable
  [16] SPDIFRXEN — SPDIFRX peripheral clocks enable
  [15] SPI3EN — SPI3 peripheral clocks enable
  [14] SPI2EN — SPI2 peripheral clocks enable
  [11] WWDGEN — WWDG clock enable
  [9] LPTIM1EN — LPTIM1 peripheral clocks enable
  [8] TIM14EN — TIM14 peripheral clock enable
  [7] TIM13EN — TIM13 peripheral clock enable
  [6] TIM12EN — TIM12 peripheral clock enable
  [n-2] TIM{n}EN (n=2..7) — TIM{n} peripheral clock enable
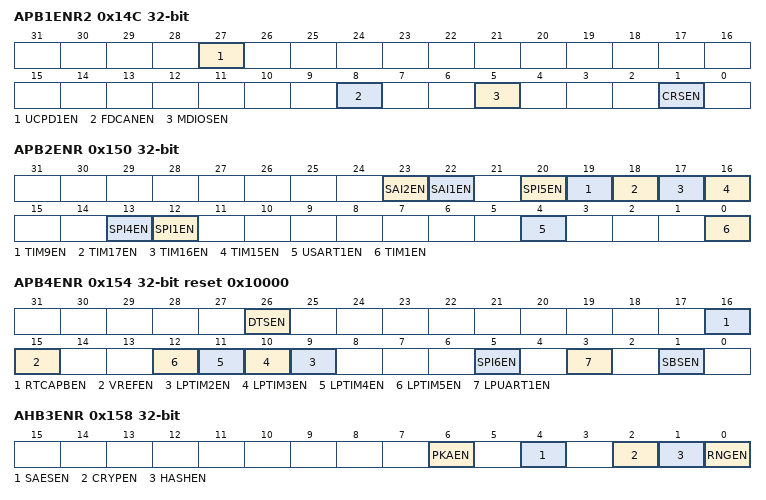
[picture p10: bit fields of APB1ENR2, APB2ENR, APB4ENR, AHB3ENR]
0x14C APB1ENR2 — RCC APB1 clock enable register 2
  [27] UCPD1EN — UCPD peripheral clock enable
  [8] FDCANEN — FDCAN peripheral clock enable
  [5] MDIOSEN — MDIOS peripheral clock enable
  [1] CRSEN — clock recovery system peripheral clock enable
0x150 APB2ENR — RCC APB2 clock enable register
  [all] fields
    values as the fields of AHB5ENR
  [23] SAI2EN — SAI2 peripheral clocks enable
  [22] SAI1EN — SAI1 peripheral clocks enable
  [20] SPI5EN — SPI5 peripheral clocks enable
  [19] TIM9EN — TIM9 peripheral clock enable
  [18] TIM17EN — TIM17 peripheral clock enable
  [17] TIM16EN — TIM16 peripheral clock enable
  [16] TIM15EN — TIM15 peripheral clock enable
  [13] SPI4EN — SPI4 Peripheral Clocks Enable
  [12] SPI1EN — SPI2S1 Peripheral Clocks Enable
  [4] USART1EN — USART1 peripheral clocks enable
  [0] TIM1EN — TIM1 peripheral clock enable
0x154 APB4ENR reset 0x10000 — RCC APB4 clock enable register
  [all] fields
    values as the fields of AHB5ENR
  [26] DTSEN — Temperature Sensor peripheral clock enable
  [16] RTCAPBEN — RTC APB clock enable
  [15] VREFEN — VREF peripheral clock enable
  [n+7] LPTIM{n}EN (n=2..5) — LPTIM{n} peripheral clocks enable
  [5] SPI6EN — SPI/I2S6 peripheral clocks enable
  [3] LPUART1EN — LPUART1 peripheral clocks enable
  [1] SBSEN — SBS peripheral clock enable
0x158 AHB3ENR — RCC AHB3 clock enable register
  [all] fields
    values as the fields of AHB5ENR
  [6] PKAEN — PKA peripheral clock enable
  [4] SAESEN — SAES peripheral clock enable
  [2] CRYPEN — CRYP peripheral clock enable
  [1] HASHEN — HASH peripheral clock enable
  [0] RNGEN — RNG peripheral clocks enable
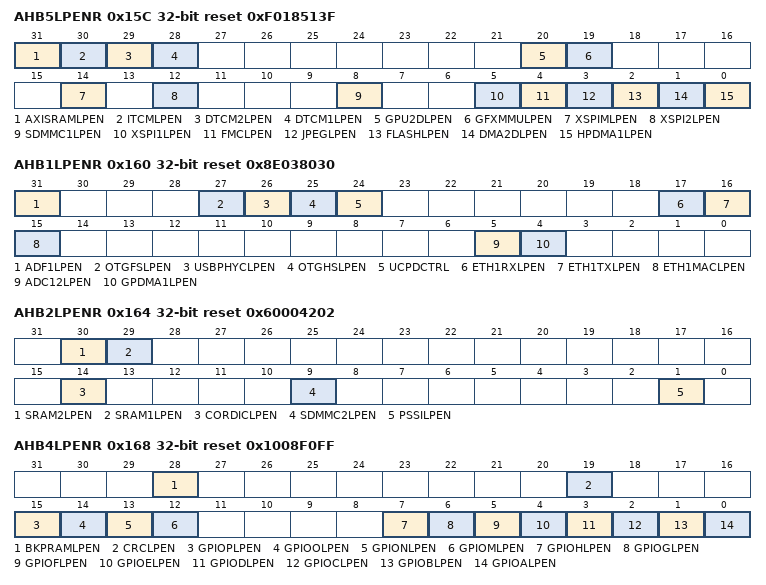
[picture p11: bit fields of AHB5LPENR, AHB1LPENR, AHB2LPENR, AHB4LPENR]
0x15C AHB5LPENR reset 0xF018513F — RCC AHB5 low-power clock enable register
  [all] fields
    0=Disabled (The selected clock is disabled during csleep mode); 1=Enabled (The selected clock is enabled during csleep mode)
  [31] AXISRAMLPEN — AXISRAM[4:1] low-power peripheral clock enable
  [30] ITCMLPEN — ITCM low-power peripheral clock enable
  [29] DTCM2LPEN — DTCM2 low-power peripheral clock enable
  [28] DTCM1LPEN — DTCM1 low-power peripheral clock enable
  [20] GPU2DLPEN — GPU2D low-power peripheral clock enable
  [19] GFXMMULPEN — GFXMMU low-power peripheral clock enable
  [14] XSPIMLPEN — XSPIM low-power peripheral clock enable
  [12] XSPI2LPEN — XSPI2 and MCE2 low-power peripheral clock enable
  [8] SDMMC1LPEN — SDMMC1 and SDMMC1 delay low-power peripheral clock enable
  [5] XSPI1LPEN — XSPI1 and MCE1 low-power peripheral clock enable
  [4] FMCLPEN — FMC and MCE3 peripheral clocks enable in low-power mode
  [3] JPEGLPEN — JPEG clock enable in low-power mode
  [2] FLASHLPEN — FLASH low-power peripheral clock enable
  [1] DMA2DLPEN — DMA2D low-power peripheral clock enable
  [0] HPDMA1LPEN — HPDMA1 low-power peripheral clock enable
0x160 AHB1LPENR reset 0x8E038030 — RCC AHB1 low-power clock enable register
  [31] ADF1LPEN — ADF clock enable in low-power mode
    values as the fields of AHB5LPENR
  [27] OTGFSLPEN — OTGFS clock enable in low-power mode
    values as the fields of AHB5LPENR
  [26] USBPHYCLPEN — USBPHYC peripheral clock enable in low-power mode
    values as the fields of AHB5LPENR
  [25] OTGHSLPEN — OTGHS peripheral clock enable in low-power mode
    values as the fields of AHB5LPENR
  [24] UCPDCTRL — USBPHYC common block power-down control
  [17] ETH1RXLPEN — ETH1 reception peripheral clock enable in low-power mode
    values as the fields of AHB5LPENR
  [16] ETH1TXLPEN — ETH1 transmission peripheral clock enable in low-power mode
    values as the fields of AHB5LPENR
  [15] ETH1MACLPEN — ETH1 MAC peripheral clock enable in low-power mode
    values as the fields of AHB5LPENR
  [5] ADC12LPEN — ADC1 and 2 peripheral clocks enable in low-power mode
    values as the fields of AHB5LPENR
  [4] GPDMA1LPEN — GPDMA1 clock enable in low-power mode
    values as the fields of AHB5LPENR
0x164 AHB2LPENR reset 0x60004202 — RCC AHB2 low-power clock enable register
  [all] fields
    values as the fields of AHB5LPENR
  [30] SRAM2LPEN — SRAM2 clock enable in low-power mode
  [29] SRAM1LPEN — SRAM1 clock enable in low-power mode
  [14] CORDICLPEN — CORDIC clock enable in low-power mode
  [9] SDMMC2LPEN — SDMMC2 and SDMMC2 delay clock enable in low-power mode
  [1] PSSILPEN — PSSI peripheral clock enable in low-power mode
0x168 AHB4LPENR reset 0x1008F0FF — RCC AHB4 low-power clock enable register
  [all] fields
    values as the fields of AHB5LPENR
  [28] BKPRAMLPEN — Backup RAM clock enable in low-power mode
  [19] CRCLPEN — CRC clock enable in low-power mode
  [15] GPIOPLPEN — GPIOP peripheral clock enable in low-power mode
  [14] GPIOOLPEN — GPIOO peripheral clock enable in low-power mode
  [13] GPIONLPEN — GPION peripheral clock enable in low-power mode
  [12] GPIOMLPEN — GPIOM peripheral clock enable in low-power mode
  [7] GPIOHLPEN — GPIOH peripheral clock enable in low-power mode
  [6] GPIOGLPEN — GPIOG peripheral clock enable in low-power mode
  [5] GPIOFLPEN — GPIOF peripheral clock enable in low-power mode
  [4] GPIOELPEN — GPIOE peripheral clock enable in low-power mode
  [3] GPIODLPEN — GPIOD peripheral clock enable in low-power mode
  [2] GPIOCLPEN — GPIOC peripheral clock enable in low-power mode
  [1] GPIOBLPEN — GPIOB peripheral clock enable in low-power mode
  [0] GPIOALPEN — GPIOA peripheral clock enable in low-power mode
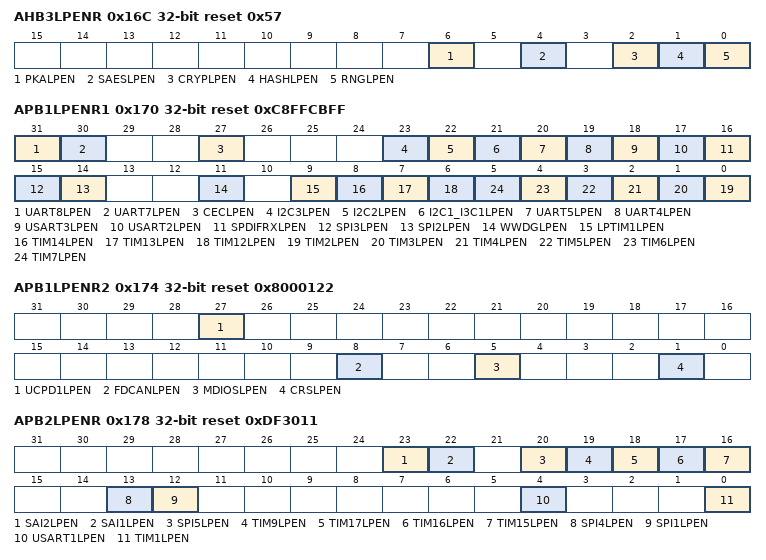
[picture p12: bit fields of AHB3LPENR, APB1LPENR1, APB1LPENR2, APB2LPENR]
0x16C AHB3LPENR reset 0x57 — RCC AHB3 low-power clock enable register
  [all] fields
    values as the fields of AHB5LPENR
  [6] PKALPEN — PKA peripheral clock enable in low-power mode
  [4] SAESLPEN — SAES peripheral clock enable in low-power mode
  [2] CRYPLPEN — CRYP peripheral clock enable in low-power mode
  [1] HASHLPEN — HASH peripheral clock enable in low-power mode
  [0] RNGLPEN — RNG peripheral clock enable in low-power mode
0x170 APB1LPENR1 reset 0xC8FFCBFF — RCC APB1 low-power clock enable register 1
  [31] UART8LPEN — UART8 peripheral clocks enable in low-power mode
  [30] UART7LPEN — UART7 peripheral clocks enable in low-power mode
  [27] CECLPEN — HDMI-CEC peripheral clocks enable in low-power mode
  [23] I2C3LPEN — I2C3 peripheral clocks enable in low-power mode
  [22] I2C2LPEN — I2C2 peripheral clocks enable in low-power mode
  [21] I2C1_I3C1LPEN — I2C1/I3C1 peripheral clocks enable in low-power mode
  [20] UART5LPEN — UART5 peripheral clocks enable in low-power mode
  [19] UART4LPEN — UART4 peripheral clocks enable in low-power mode
  [18] USART3LPEN — USART3 peripheral clocks enable in low-power mode
  [17] USART2LPEN — USART2 peripheral clocks enable in low-power mode
  [16] SPDIFRXLPEN — SPDIFRX peripheral clocks enable in low-power mode
  [15] SPI3LPEN — SPI3 peripheral clocks enable in low-power mode
  [14] SPI2LPEN — SPI2 peripheral clocks enable in low-power mode
  [11] WWDGLPEN — WWDG clock enable in low-power mode
  [9] LPTIM1LPEN — LPTIM1 peripheral clocks enable in low-power mode
  [8] TIM14LPEN — TIM14 peripheral clock enable in low-power mode
  [7] TIM13LPEN — TIM13 peripheral clock enable in low-power mode
  [6] TIM12LPEN — TIM12 peripheral clock enable in low-power mode
  [n-2] TIM{n}LPEN (n=2..7) — TIM{n} peripheral clock enable in low-power mode
0x174 APB1LPENR2 reset 0x8000122 — RCC APB1 low-power clock enable register 2
  [27] UCPD1LPEN — UCPD peripheral clock enable in low-power mode
  [8] FDCANLPEN — FDCAN peripheral clock enable in low-power mode
  [5] MDIOSLPEN — MDIOS peripheral clock enable in low-power mode
  [1] CRSLPEN — clock recovery system peripheral clock enable in low-power mode
0x178 APB2LPENR reset 0xDF3011 — RCC APB2 low-power clock enable register
  [all] fields
    values as the fields of AHB5LPENR
  [23] SAI2LPEN — SAI2 peripheral clocks enable in low-power mode
  [22] SAI1LPEN — SAI1 peripheral clocks enable in low-power mode
  [20] SPI5LPEN — SPI5 peripheral clocks enable in low-power mode
  [19] TIM9LPEN — TIM9 peripheral clock enable in low-power mode
  [18] TIM17LPEN — TIM17 peripheral clock enable in low-power mode
  [17] TIM16LPEN — TIM16 peripheral clock enable in low-power mode
  [16] TIM15LPEN — TIM15 peripheral clock enable in low-power mode
  [13] SPI4LPEN — SPI4 peripheral clock enable in low-power mode
  [12] SPI1LPEN — SPI2S1 peripheral clock enable in low-power mode
  [4] USART1LPEN — USART1 peripheral clock enable in low-power mode
  [0] TIM1LPEN — TIM1 peripheral clock enable in low-power mode
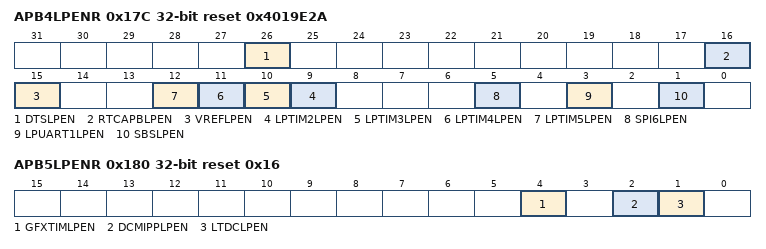
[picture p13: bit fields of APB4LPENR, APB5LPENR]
0x17C APB4LPENR reset 0x4019E2A — RCC APB4 low-power clock enable register
  [all] fields
    values as the fields of AHB5LPENR
  [26] DTSLPEN — temperature sensor peripheral clock enable in low-power mode
  [16] RTCAPBLPEN — RTC APB clock enable in low-power mode
  [15] VREFLPEN — VREF peripheral clock enable in low-power mode
  [n+7] LPTIM{n}LPEN (n=2..5) — LPTIM{n} peripheral clocks enable in low-power mode
  [5] SPI6LPEN — SPI/I2S6 peripheral clocks enable in low-power mode
  [3] LPUART1LPEN — LPUART1 peripheral clocks enable in low-power mode
  [1] SBSLPEN — SBS peripheral clock enable in low-power mode
0x180 APB5LPENR reset 0x16 — RCC APB5 low-power clock enable register
  [all] fields
    values as the fields of AHB5LPENR
  [4] GFXTIMLPEN — GFXTIM peripheral clock enable in low-power mode
  [2] DCMIPPLPEN — DCMIPP peripheral clock enable in low-power mode
  [1] LTDCLPEN — LTDC peripheral clock enable in low-power mode
